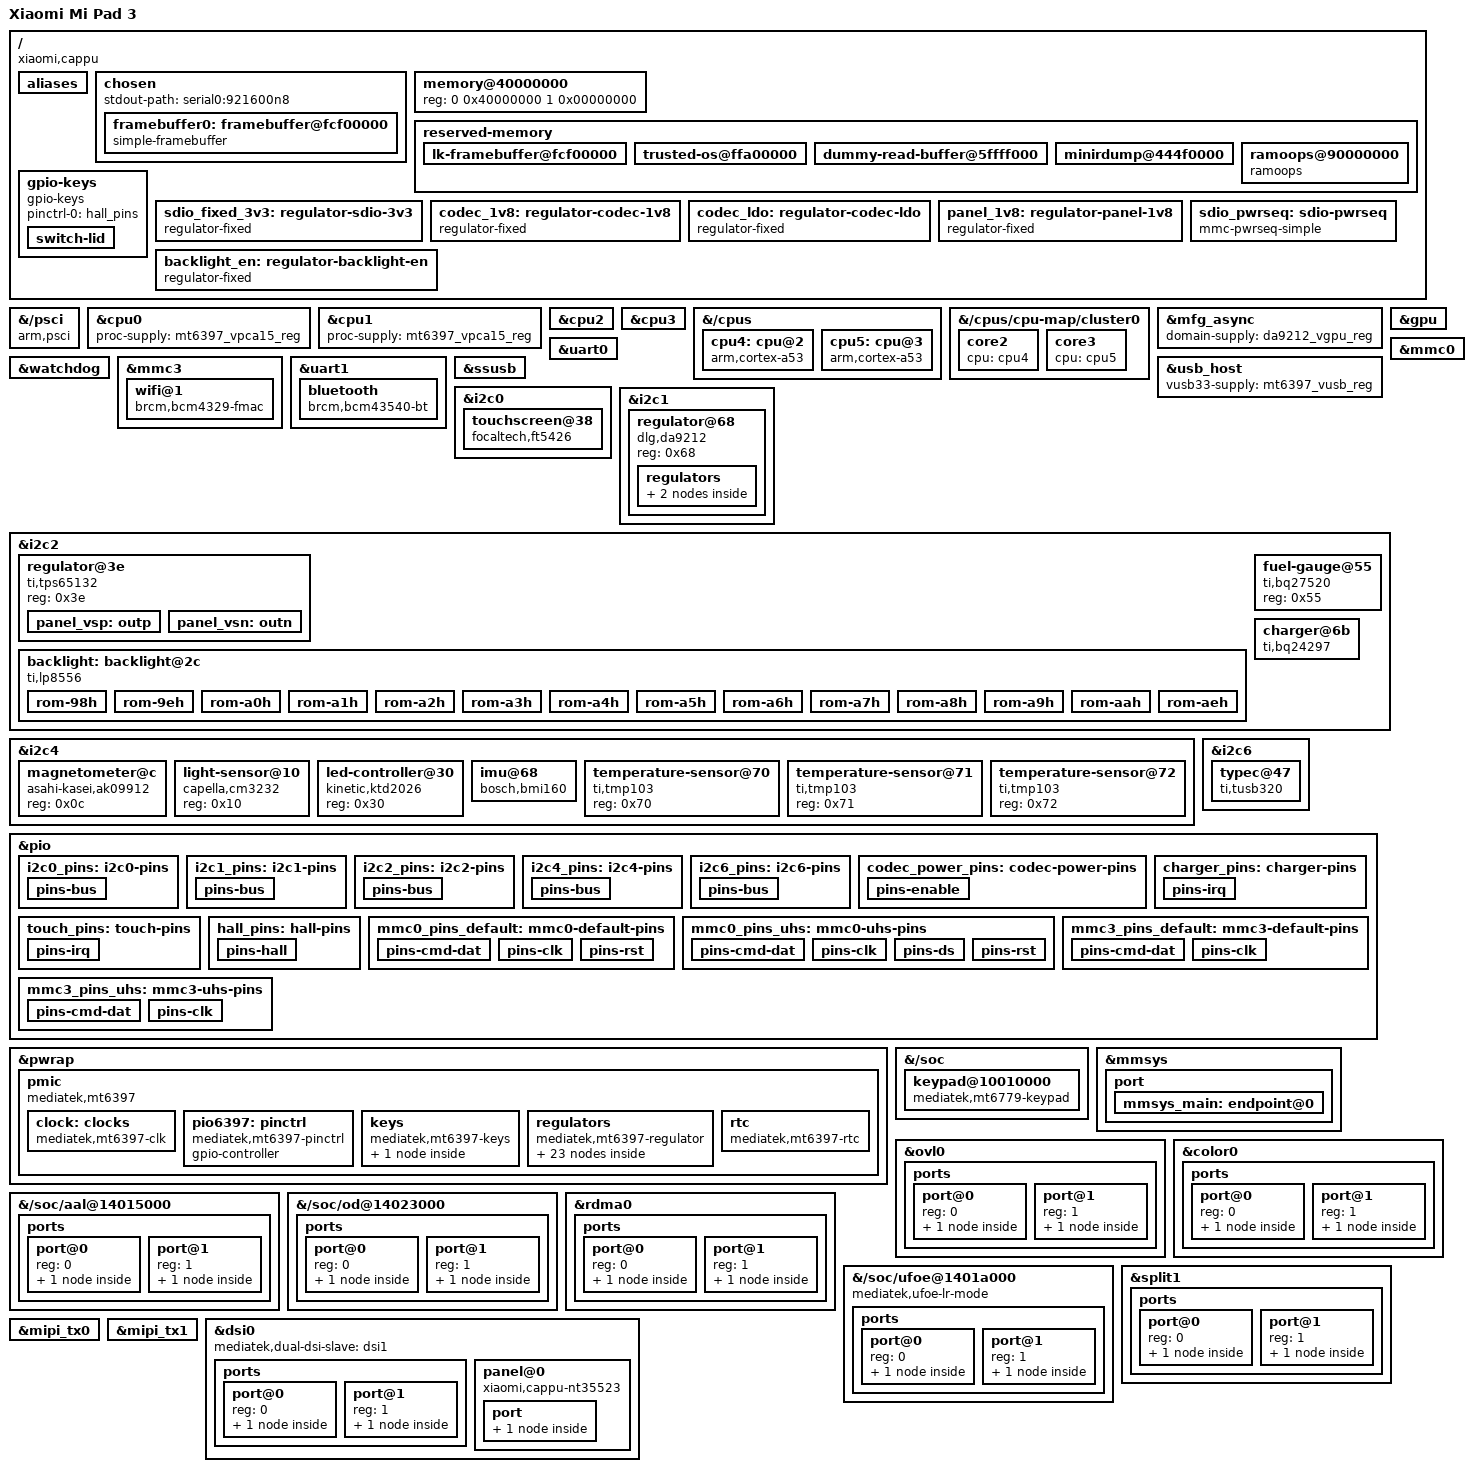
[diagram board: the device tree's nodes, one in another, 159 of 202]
// SPDX-License-Identifier: GPL-2.0-only
/*
 * Xiaomi Mi Pad 3 (cappu): MediaTek MT8176 (MT8173 family, four Cortex-A53 and two
 * Cortex-A72), 4 GB RAM, 1536x2048 dual-link DSI panel.
 *
 * Board facts come from the stock 3.18 device tree (xiaomi8176_tb_c9_n) as the
 * bootloader passes it, the stock I2C device list and the registers the stock LK and
 * kernel leave behind. Layout and PMIC regulator settings follow mt8173-elm.dtsi.
 *
 * Working: all six CPUs, eMMC, USB peripheral, PMIC and DA9212, keys, pstore, charger
 * and fuel gauge, the PowerVR GX6250, and the display through mediatek-drm with panel
 * power and backlight. The BCM4356 Wi-Fi probes.
 * Not yet: IOMMU for the display path, touchscreen, Bluetooth, audio, cameras, USB
 * role switching, cpufreq and cpuidle.
 *
 * The stock LK boots this as an Android boot image and keeps only the first 99
 * characters of the image's command line, so the kernel needs its own
 * (CONFIG_CMDLINE). While the clock, power-domain and regulator handover is not
 * complete it must contain
 *   clk_ignore_unused pd_ignore_unused regulator_ignore_unused
 * See arch/arm64/configs/cappu_spike.config.
 */

/dts-v1/;
#include <dt-bindings/gpio/gpio.h>
#include <dt-bindings/input/input.h>
#include <dt-bindings/interrupt-controller/irq.h>
#include <dt-bindings/pinctrl/mt65xx.h>
#include <dt-bindings/regulator/dlg,da9211-regulator.h>
#include "mt8173.dtsi"

/ {
	model = "Xiaomi Mi Pad 3";
	chassis-type = "tablet";
	compatible = "xiaomi,cappu", "mediatek,mt8173";

	aliases {
		mmc0 = &mmc0;
		mmc1 = &mmc3;
		serial0 = &uart0;
		serial1 = &uart1;
	};

	chosen {
		#address-cells = <2>;
		#size-cells = <2>;
		ranges;
		stdout-path = "serial0:921600n8";

		/*
		 * The bootloader leaves the panel scanning out this buffer (stock fb0: 1536x2048,
		 * 32 bpp, stride 6144, three buffers; the first one is on screen). It is the
		 * console until mediatek-drm binds and removes it; until then nothing may turn
		 * the display path off, hence the *_ignore_unused flags on the command line.
		 */
		framebuffer0: framebuffer@fcf00000 {
			compatible = "simple-framebuffer";
			reg = <0 0xfcf00000 0 (1536 * 2048 * 4)>;
			width = <1536>;
			height = <2048>;
			stride = <(1536 * 4)>;
			/* proven by the canary payload: red written as 0xffff0000 shows blue */
			format = "a8b8g8r8";
			/* holds the display power domain on while simpledrm is bound */
			power-domains = <&spm MT8173_POWER_DOMAIN_MM>;
		};
	};

	memory@40000000 {
		device_type = "memory";
		/* 4 GB at 0x40000000-0x13fffffff; the bootloader rewrites this node */
		reg = <0 0x40000000 1 0x00000000>;
	};

	/*
	 * LK (boot_linux_fdt, via the helper at 0x41e0447c) adds two nodes here before
	 * starting the kernel: secos-reserved-memory (0xffa00000, 6 MB, trusted OS) and
	 * fb-reserved-memory (0xfcf00000, 43 MB, its framebuffer), both no-map. This node
	 * must exist and must not already contain nodes with those names: if
	 * fdt_add_subnode() fails, LK prints a warning and then refuses to boot.
	 */
	reserved-memory {
		#address-cells = <2>;
		#size-cells = <2>;
		ranges;

		/*
		 * The same two regions LK adds as fb-reserved-memory and
		 * secos-reserved-memory, under other names so LK's fdt_add_subnode() still
		 * succeeds. Spike boots 1-3 went black, with no earlycon text, consistent with
		 * these not being reserved: swiotlb's zeroed 64 MB below 4 GB would cover
		 * the scanned-out framebuffer and the trusted OS. Overlap with LK's nodes only
		 * costs an "OVERLAP DETECTED" message.
		 */
		lk-framebuffer@fcf00000 {
			reg = <0 0xfcf00000 0 0x2b00000>;
			no-map;
		};

		trusted-os@ffa00000 {
			reg = <0 0xffa00000 0 0x600000>;
			no-map;
		};

		/* stock: "vcore_dvfs-reserve-memory", read by the DRAM DVFS hardware */
		dummy-read-buffer@5ffff000 {
			reg = <0 0x5ffff000 0 0x2000>;
			no-map;
		};

		/* stock: "minirdump-reserve-memory", crash record area read by LK */
		minirdump@444f0000 {
			reg = <0 0x444f0000 0 0x10000>;
			no-map;
		};

		/*
		 * pstore, so the log of a failed boot can be read after the next one. Not the
		 * stock RAM console at 0x44400000: recovery clears that (seen on the MT8173
		 * Fire HD 10, which uses this address). Clear of every LK buffer: kernel
		 * 0x40080000-0x41c80000, LK 0x41e00000, staging 0x45000000, ramdisk
		 * 0x49000000, DTB 0x4e000000.
		 */
		/*
		 * Laid out so LineageOS's 3.18 ramoops reads the console zone after a warm
		 * reset. Its command line can only carry ramoops.mem_address=0x90000000
		 * ramoops.mem_size=0xc0000 (LK keeps 99 characters), and with its default zone
		 * sizes its console zone is 0x9007f000 + 0x10000. Here: 0x7f000 of 0x1000
		 * dmesg records, then the 0x10000 console zone at the same address.
		 */
		ramoops@90000000 {
			compatible = "ramoops";
			reg = <0 0x90000000 0 0x8f000>;
			console-size = <0x10000>;
			record-size = <0x1000>;
		};
	};

	gpio-keys {
		compatible = "gpio-keys";
		pinctrl-names = "default";
		pinctrl-0 = <&hall_pins>;

		/* stock "lid_front" */
		switch-lid {
			label = "Cover";
			gpios = <&pio 116 GPIO_ACTIVE_LOW>;
			linux,input-type = <EV_SW>;
			linux,code = <SW_LID>;
			wakeup-source;
		};

		/*
		 * The second hall sensor ("lid_back", GPIO70, active low) reports switch 0x12 on
		 * stock, a Xiaomi-only code above SW_MAX. It has no standard meaning, so it is
		 * left out.
		 */
	};

	/* BCM4356 module supply: comes straight from the system rail, not switchable */
	sdio_fixed_3v3: regulator-sdio-3v3 {
		compatible = "regulator-fixed";
		regulator-name = "sdio_3v3";
		regulator-min-microvolt = <3300000>;
		regulator-max-microvolt = <3300000>;
		regulator-always-on;
	};

	/*
	 * RT5659 codec supplies: 1.8 V (stock 1v8-gpio, GPIO34) and the codec LDO (stock
	 * ldo-gpio, GPIO35). LK leaves both pins muxed to PCM0, so both rails are off, and
	 * with both off the unpowered codec holds SDA and SCL of i2c6 low: every transfer
	 * on that bus times out, the USB-C controller's included. Either rail frees the
	 * bus (measured). Kept on until a codec driver takes them.
	 */
	codec_1v8: regulator-codec-1v8 {
		compatible = "regulator-fixed";
		regulator-name = "codec_1v8";
		regulator-min-microvolt = <1800000>;
		regulator-max-microvolt = <1800000>;
		gpio = <&pio 34 GPIO_ACTIVE_HIGH>;
		enable-active-high;
		pinctrl-names = "default";
		pinctrl-0 = <&codec_power_pins>;
		regulator-boot-on;
		regulator-always-on;
	};

	codec_ldo: regulator-codec-ldo {
		compatible = "regulator-fixed";
		regulator-name = "codec_ldo";
		gpio = <&pio 35 GPIO_ACTIVE_HIGH>;
		enable-active-high;
		regulator-boot-on;
		regulator-always-on;
	};

	/* Panel logic supply (stock GPIO_LCD_1V8_EN, GPIO71); LK hands over with it on */
	panel_1v8: regulator-panel-1v8 {
		compatible = "regulator-fixed";
		regulator-name = "panel_1v8";
		regulator-min-microvolt = <1800000>;
		regulator-max-microvolt = <1800000>;
		gpio = <&pio 71 GPIO_ACTIVE_HIGH>;
		enable-active-high;
		regulator-boot-on;
	};

	/* LP8556 enable pin (stock lp8556_gpio_enable, GPIO103); on at handover */
	backlight_en: regulator-backlight-en {
		compatible = "regulator-fixed";
		regulator-name = "backlight_en";
		gpio = <&pio 103 GPIO_ACTIVE_HIGH>;
		enable-active-high;
		regulator-boot-on;
	};

	/* BCM4356 WL_REG_ON (stock wifi_reg_on: GPIO31) */
	sdio_pwrseq: sdio-pwrseq {
		compatible = "mmc-pwrseq-simple";
		reset-gpios = <&pio 31 GPIO_ACTIVE_LOW>;
		post-power-on-delay-ms = <50>;
	};
};

/*
 * Stock firmware declares PSCI 0.1 only (its PSCI 0.2 is broken on the MT8173 Fire HD 10
 * too); mt8173.dtsi already carries the stock function IDs. Stock "mt-boot" is PSCI CPU_ON
 * followed by the kernel powering the core through SPM MTCMOS: this firmware's CPU_ON
 * does not power cores. drivers/soc/mediatek/mtk-cpu-mtcmos.c (from the Fire HD 10 port,
 * extended to the MT8176's four A53s) does that after CPU_ON. CPU idle states need
 * CPU_SUSPEND, which has the same gap.
 */
&{/psci} {
	compatible = "arm,psci";
};

&cpu0 {
	/delete-property/ cpu-idle-states;
	proc-supply = <&mt6397_vpca15_reg>;
};

&cpu1 {
	/delete-property/ cpu-idle-states;
	proc-supply = <&mt6397_vpca15_reg>;
};

&cpu2 {
	/delete-property/ cpu-idle-states;
	proc-supply = <&da9212_vcpu_reg>;
	sram-supply = <&mt6397_vsramca7_reg>;
};

&cpu3 {
	/delete-property/ cpu-idle-states;
	proc-supply = <&da9212_vcpu_reg>;
	sram-supply = <&mt6397_vsramca7_reg>;
};

/*
 * MT8176 has four A53s in cluster 0 (MPIDR 0x0-0x3) and two A72s in cluster 1; the
 * stock ATF log brings up mt_on[0:1..3] and [256:0..1]. mt8173.dtsi describes the
 * MT8173's 2+2, so add the two extra A53s. Their logical numbers come after the
 * A72s (DT order): 0-1 A53, 2-3 A72, 4-5 A53.
 */
&{/cpus} {
	cpu4: cpu@2 {
		device_type = "cpu";
		compatible = "arm,cortex-a53";
		reg = <0x002>;
		enable-method = "psci";
		#cooling-cells = <2>;
		dynamic-power-coefficient = <263>;
		clocks = <&infracfg CLK_INFRA_CA53SEL>,
			 <&apmixedsys CLK_APMIXED_MAINPLL>;
		clock-names = "cpu", "intermediate";
		operating-points-v2 = <&cluster0_opp>;
		capacity-dmips-mhz = <740>;
		proc-supply = <&mt6397_vpca15_reg>;
	};

	cpu5: cpu@3 {
		device_type = "cpu";
		compatible = "arm,cortex-a53";
		reg = <0x003>;
		enable-method = "psci";
		#cooling-cells = <2>;
		dynamic-power-coefficient = <263>;
		clocks = <&infracfg CLK_INFRA_CA53SEL>,
			 <&apmixedsys CLK_APMIXED_MAINPLL>;
		clock-names = "cpu", "intermediate";
		operating-points-v2 = <&cluster0_opp>;
		capacity-dmips-mhz = <740>;
		proc-supply = <&mt6397_vpca15_reg>;
	};
};

&{/cpus/cpu-map/cluster0} {
	core2 {
		cpu = <&cpu4>;
	};

	core3 {
		cpu = <&cpu5>;
	};
};

&mfg_async {
	domain-supply = <&da9212_vgpu_reg>;
};

/*
 * SMI and M4U. mediatek-drm needs the IOMMU to scan out buffers that are not
 * physically contiguous, which is what the GPU driver hands it (Vulkan presenting
 * straight to the panel).
 *
 * All six larbs stay enabled, as in mt8173.dtsi: the IOMMU driver refuses to register
 * if any device with an "iommus" property sits on a larb that is not there (-EINVAL
 * from its probe_device), and the codec, camera and MDP nodes all have one.
 *
 * LK hands over with OVL0 reading its framebuffer by physical address through larb0.
 * When larb0 is first resumed for the overlay driver's probe, that read goes through
 * the IOMMU and faults (and the larb's clocks are gated again after the probe) until
 * mediatek-drm, a few milliseconds later, stops LK's stream and programs its own
 * buffer. That costs a burst of "fault" messages and nothing else.
 */

/* PowerVR GX6250: needs powervr.exp_hw_support=1 and firmware rogue_4.40.2.51_v1.fw */
&gpu {
	status = "okay";
};

/* stock console ttyMT0 at 921600, on test pads */
&uart0 {
	status = "okay";
};

&watchdog {
	/*
	 * LK leaves it disabled (a halted payload sat for many minutes without a reset).
	 * Keep the external (PMIC) reset: a TOPRGU reset without it, tried on 2026-11-21,
	 * left the board stuck with a black screen and no preloader on USB.
	 */
	status = "okay";
};

&mmc0 {
	status = "okay";
	pinctrl-names = "default", "state_uhs";
	pinctrl-0 = <&mmc0_pins_default>;
	pinctrl-1 = <&mmc0_pins_uhs>;
	bus-width = <8>;
	max-frequency = <200000000>;
	cap-mmc-highspeed;
	mmc-hs200-1_8v;
	mmc-hs400-1_8v;
	cap-mmc-hw-reset;
	hs400-ds-delay = <0x14015>;
	/* stock hs200_cmd_int_delay and hs400_cmd_int_delay; stock cmd_resp_sel is 0 */
	mediatek,hs200-cmd-int-delay = <26>;
	mediatek,hs400-cmd-int-delay = <14>;
	vmmc-supply = <&mt6397_vemc_3v3_reg>;
	vqmmc-supply = <&mt6397_vio18_reg>;
	assigned-clocks = <&topckgen CLK_TOP_MSDC50_0_SEL>;
	assigned-clock-parents = <&topckgen CLK_TOP_MSDCPLL_D2>;
	non-removable;
};

/*
 * BCM4356 Wi-Fi. Needs brcmfmac4356-sdio.bin and the board nvram from the stock vendor
 * image. The chip also needs the MT6397 RTC 32 kHz output (RTC_CON.F32KOB clear), which
 * stock switches on with rtc_gpio_enable_32k() before raising WL_REG_ON. Mainline has no
 * consumer for it; the bit is battery-backed, so it stays as stock last left it.
 */
&mmc3 {
	status = "okay";
	pinctrl-names = "default", "state_uhs";
	pinctrl-0 = <&mmc3_pins_default>;
	pinctrl-1 = <&mmc3_pins_uhs>;
	bus-width = <4>;
	max-frequency = <200000000>;
	cap-sd-highspeed;
	sd-uhs-sdr50;
	sd-uhs-sdr104;
	keep-power-in-suspend;
	wakeup-source;
	cap-sdio-irq;
	cap-power-off-card;
	non-removable;
	mmc-pwrseq = <&sdio_pwrseq>;
	vmmc-supply = <&sdio_fixed_3v3>;
	/* stock declares no supplies; the module I/O is 1.8 V */
	vqmmc-supply = <&mt6397_vio18_reg>;
	#address-cells = <1>;
	#size-cells = <0>;

	wifi@1 {
		compatible = "brcm,bcm4329-fmac";
		reg = <1>;
		/*
		 * stock wifi_host_wake: GPIO30, used by bcmdhd as a level-high OOB interrupt
		 * (the "interrupts = <2 ...>" in the stock node is unused)
		 */
		interrupts-extended = <&pio 30 IRQ_TYPE_LEVEL_HIGH>;
		interrupt-names = "host-wake";
	};
};

/* BCM4356 Bluetooth on UART1 (stock /dev/ttyMT1), H4 with RTS/CTS */
&uart1 {
	status = "okay";
	/* TODO stage 2: RTS/CTS pin mux, taken from the stock uart1 pin states */

	bluetooth {
		/* the Bluetooth core of the BCM4356 is a BCM4354A2 */
		compatible = "brcm,bcm43540-bt";
		max-speed = <3000000>;
		shutdown-gpios = <&pio 32 GPIO_ACTIVE_HIGH>;		/* stock bcm_bt_reg_on */
		device-wakeup-gpios = <&pio 28 GPIO_ACTIVE_HIGH>;	/* stock bcm_bt_dev_wake */
		host-wakeup-gpios = <&pio 37 GPIO_ACTIVE_HIGH>;		/* stock bcm_bt_host_wake */
	};
};

/*
 * USB-C, USB 2.0 only. Peripheral mode for adb/RNDIS during bring-up.
 * TODO: role switching from the TUSB320.
 */
&ssusb {
	dr_mode = "peripheral";
	vusb33-supply = <&mt6397_vusb_reg>;
	status = "okay";
};

&usb_host {
	vusb33-supply = <&mt6397_vusb_reg>;
	status = "okay";
};

/* I2C: controller numbering matches the stock tree; the stock Linux bus number is N + 4 */

&i2c0 {
	status = "okay";
	pinctrl-names = "default";
	pinctrl-0 = <&i2c0_pins>;
	clock-frequency = <400000>;

	touchscreen@38 {
		/* FocalTech FT5x46; register map of the FT5426/FT5506 family */
		compatible = "focaltech,ft5426";
		reg = <0x38>;
		interrupts-extended = <&pio 104 IRQ_TYPE_EDGE_FALLING>;
		pinctrl-names = "default";
		pinctrl-0 = <&touch_pins>;
		reset-gpios = <&pio6397 12 GPIO_ACTIVE_LOW>;
		/* stock: vtouch = VGP6 (3.3 V), vtouchio = VGP4 (1.8 V) */
		vcc-supply = <&mt6397_vgp6_reg>;
		iovcc-supply = <&mt6397_vgp4_reg>;
		touchscreen-size-x = <1536>;
		touchscreen-size-y = <2048>;
	};
};

/* CPU and GPU buck */
&i2c1 {
	status = "okay";
	pinctrl-names = "default";
	pinctrl-0 = <&i2c1_pins>;
	clock-frequency = <1500000>;

	regulator@68 {
		compatible = "dlg,da9212";
		reg = <0x68>;
		/*
		 * The stock tree wires no interrupt (the Chromebooks use GPIO15). The driver runs
		 * without one; the binding wants one, so this fails dtbs_check until the pin is
		 * known or the binding relaxed.
		 */

		regulators {
			da9212_vcpu_reg: BUCKA {
				regulator-name = "VBUCKA";
				regulator-min-microvolt = <700000>;
				regulator-max-microvolt = <1310000>;
				regulator-min-microamp = <2000000>;
				regulator-max-microamp = <4400000>;
				regulator-ramp-delay = <10000>;
				regulator-always-on;
				/* stock: enable on PMIC GPIO24 */
				enable-gpios = <&pio6397 24 GPIO_ACTIVE_HIGH>;
				regulator-allowed-modes = <DA9211_BUCK_MODE_SYNC
							   DA9211_BUCK_MODE_AUTO>;
			};

			da9212_vgpu_reg: BUCKB {
				regulator-name = "VBUCKB";
				regulator-min-microvolt = <700000>;
				regulator-max-microvolt = <1310000>;
				regulator-min-microamp = <2000000>;
				regulator-max-microamp = <3000000>;
				regulator-ramp-delay = <10000>;
			};
		};
	};
};

/* battery, charger, backlight, panel bias */
&i2c2 {
	status = "okay";
	pinctrl-names = "default";
	pinctrl-0 = <&i2c2_pins>;
	clock-frequency = <400000>;

	/*
	 * Panel bias, +/-5.6 V as the stock driver programs it (register value 0x10).
	 * Positive rail enable is GPIO8, negative GPIO13; both on at handover.
	 */
	regulator@3e {
		compatible = "ti,tps65132";
		reg = <0x3e>;

		panel_vsp: outp {
			regulator-name = "panel_vsp";
			regulator-min-microvolt = <5600000>;
			regulator-max-microvolt = <5600000>;
			enable-gpios = <&pio 8 GPIO_ACTIVE_HIGH>;
			regulator-boot-on;
		};

		panel_vsn: outn {
			regulator-name = "panel_vsn";
			regulator-min-microvolt = <5600000>;
			regulator-max-microvolt = <5600000>;
			enable-gpios = <&pio 13 GPIO_ACTIVE_HIGH>;
			regulator-boot-on;
		};
	};

	/*
	 * Backlight. Control mode and EPROM values are the stock tree's: brightness is
	 * the I2C register times the PWM the panel itself outputs (its CABC), which
	 * the panel driver leaves at full scale.
	 */
	backlight: backlight@2c {
		compatible = "ti,lp8556";
		reg = <0x2c>;
		enable-supply = <&backlight_en>;
		bl-name = "lcd-backlight";
		dev-ctrl = /bits/ 8 <0x83>;
		init-brt = /bits/ 8 <0x50>;

		rom-98h {
			rom-addr = /bits/ 8 <0x98>;
			rom-val = /bits/ 8 <0x80>;
		};

		rom-9eh {
			rom-addr = /bits/ 8 <0x9e>;
			rom-val = /bits/ 8 <0x21>;
		};

		rom-a0h {
			rom-addr = /bits/ 8 <0xa0>;
			rom-val = /bits/ 8 <0xff>;
		};

		rom-a1h {
			rom-addr = /bits/ 8 <0xa1>;
			rom-val = /bits/ 8 <0x3f>;
		};

		rom-a2h {
			rom-addr = /bits/ 8 <0xa2>;
			rom-val = /bits/ 8 <0x20>;
		};

		rom-a3h {
			rom-addr = /bits/ 8 <0xa3>;
			rom-val = /bits/ 8 <0x58>;
		};

		rom-a4h {
			rom-addr = /bits/ 8 <0xa4>;
			rom-val = /bits/ 8 <0x72>;
		};

		rom-a5h {
			rom-addr = /bits/ 8 <0xa5>;
			rom-val = /bits/ 8 <0x24>;
		};

		rom-a6h {
			rom-addr = /bits/ 8 <0xa6>;
			rom-val = /bits/ 8 <0x80>;
		};

		rom-a7h {
			rom-addr = /bits/ 8 <0xa7>;
			rom-val = /bits/ 8 <0xf5>;
		};

		rom-a8h {
			rom-addr = /bits/ 8 <0xa8>;
			rom-val = /bits/ 8 <0x24>;
		};

		rom-a9h {
			rom-addr = /bits/ 8 <0xa9>;
			rom-val = /bits/ 8 <0xb2>;
		};

		rom-aah {
			rom-addr = /bits/ 8 <0xaa>;
			rom-val = /bits/ 8 <0x8f>;
		};

		rom-aeh {
			rom-addr = /bits/ 8 <0xae>;
			rom-val = /bits/ 8 <0x0f>;
		};
	};

	fuel-gauge@55 {
		compatible = "ti,bq27520";
		reg = <0x55>;
	};

	charger@6b {
		compatible = "ti,bq24297";
		reg = <0x6b>;
		/* stock: EINT105, falling edge; the pin (MSDC2_CMD) must be muxed as GPIO */
		interrupts-extended = <&pio 105 IRQ_TYPE_EDGE_FALLING>;
		pinctrl-names = "default";
		pinctrl-0 = <&charger_pins>;
		/*
		 * Keep LK's charger setup. A register reset drops the input current limit to
		 * the defaults, below what the tablet draws with its screen on, so it drains
		 * while plugged in (flat battery on 2026-11-22).
		 */
		disable-reset;
	};
};

/* i2c3: cameras (no mainline driver for the MT8173 camera ISP) */

&i2c4 {
	status = "okay";
	pinctrl-names = "default";
	pinctrl-0 = <&i2c4_pins>;
	clock-frequency = <400000>;

	magnetometer@c {
		compatible = "asahi-kasei,ak09912";
		reg = <0x0c>;
	};

	light-sensor@10 {
		compatible = "capella,cm3232";
		reg = <0x10>;
	};

	led-controller@30 {
		compatible = "kinetic,ktd2026";
		reg = <0x30>;
		#address-cells = <1>;
		#size-cells = <0>;
		/* TODO: LED channel nodes */
	};

	/* stock splits this chip into gsensor@68 and gyro@69; it is one BMI160 */
	imu@68 {
		compatible = "bosch,bmi160";
		reg = <0x68>;
		interrupts-extended = <&pio 14 IRQ_TYPE_EDGE_RISING>;
	};

	temperature-sensor@70 {
		compatible = "ti,tmp103";
		reg = <0x70>;
	};

	temperature-sensor@71 {
		compatible = "ti,tmp103";
		reg = <0x71>;
	};

	temperature-sensor@72 {
		compatible = "ti,tmp103";
		reg = <0x72>;
	};
};

&i2c6 {
	status = "okay";
	pinctrl-names = "default";
	pinctrl-0 = <&i2c6_pins>;
	clock-frequency = <400000>;

	/*
	 * TODO stage 2: RT5659 codec at 0x1b (irq GPIO36, reset GPIO33, 1.8 V enable GPIO34,
	 * LDO enable GPIO35), TFA98xx amplifiers at 0x34 and 0x37, and a machine driver for
	 * the MT8173 AFE with this codec.
	 */

	/*
	 * The stock tree says 0x60, but the device answers at 0x47. No driver binds in the
	 * spike (extcon-usbc-tusb320 is not built in); init sets the chip up instead, see
	 * usbc_sink() in cappu-helper.c. Mainline's driver would need two things first:
	 * clear DISABLE_RD_RP (register 0x45 bit 2), which the stock kernel's shutdown can
	 * leave set, and prefer the sink role, since this board cannot source VBUS.
	 */
	typec@47 {
		compatible = "ti,tusb320";
		reg = <0x47>;
		interrupts-extended = <&pio 88 IRQ_TYPE_LEVEL_LOW>;
	};
};

&pio {
	/*
	 * I2C pin states from the stock tree. LK only muxes the buses it uses itself (i2c1
	 * and i2c2); without these, transfers on the others time out.
	 */
	i2c0_pins: i2c0-pins {
		pins-bus {
			pinmux = <MT8173_PIN_45_SDA0__FUNC_SDA0>,
				 <MT8173_PIN_46_SCL0__FUNC_SCL0>;
			bias-disable;
		};
	};

	i2c1_pins: i2c1-pins {
		pins-bus {
			pinmux = <MT8173_PIN_125_SDA1__FUNC_SDA1>,
				 <MT8173_PIN_126_SCL1__FUNC_SCL1>;
			bias-disable;
		};
	};

	i2c2_pins: i2c2-pins {
		pins-bus {
			pinmux = <MT8173_PIN_43_SDA2__FUNC_SDA2>,
				 <MT8173_PIN_44_SCL2__FUNC_SCL2>;
			bias-disable;
		};
	};

	i2c4_pins: i2c4-pins {
		pins-bus {
			pinmux = <MT8173_PIN_133_SDA4__FUNC_SDA4>,
				 <MT8173_PIN_134_SCL4__FUNC_SCL4>;
			bias-disable;
		};
	};

	/* the pad function is named SDA5/SCL5; it belongs to the controller at 0x11013000 */
	i2c6_pins: i2c6-pins {
		pins-bus {
			pinmux = <MT8173_PIN_100_MSDC2_DAT0__FUNC_SDA5>,
				 <MT8173_PIN_101_MSDC2_DAT1__FUNC_SCL5>;
			bias-disable;
		};
	};

	codec_power_pins: codec-power-pins {
		pins-enable {
			pinmux = <MT8173_PIN_34_DAIPCMIN__FUNC_GPIO34>,
				 <MT8173_PIN_35_DAIPCMOUT__FUNC_GPIO35>;
			bias-disable;
		};
	};

	charger_pins: charger-pins {
		pins-irq {
			pinmux = <MT8173_PIN_105_MSDC2_CMD__FUNC_GPIO105>;
			input-enable;
			bias-pull-up;
		};
	};

	touch_pins: touch-pins {
		pins-irq {
			pinmux = <MT8173_PIN_104_MSDC2_CLK__FUNC_GPIO104>;
			input-enable;
			bias-pull-up;
		};
	};

	hall_pins: hall-pins {
		pins-hall {
			pinmux = <MT8173_PIN_116_UCTS0__FUNC_GPIO116>,
				 <MT8173_PIN_70_SPI_MI__FUNC_GPIO70>;
			input-enable;
			bias-pull-up;
		};
	};

	/* MSDC pin settings below are the stock values */
	mmc0_pins_default: mmc0-default-pins {
		pins-cmd-dat {
			pinmux = <MT8173_PIN_57_MSDC0_DAT0__FUNC_MSDC0_DAT0>,
				 <MT8173_PIN_58_MSDC0_DAT1__FUNC_MSDC0_DAT1>,
				 <MT8173_PIN_59_MSDC0_DAT2__FUNC_MSDC0_DAT2>,
				 <MT8173_PIN_60_MSDC0_DAT3__FUNC_MSDC0_DAT3>,
				 <MT8173_PIN_61_MSDC0_DAT4__FUNC_MSDC0_DAT4>,
				 <MT8173_PIN_62_MSDC0_DAT5__FUNC_MSDC0_DAT5>,
				 <MT8173_PIN_63_MSDC0_DAT6__FUNC_MSDC0_DAT6>,
				 <MT8173_PIN_64_MSDC0_DAT7__FUNC_MSDC0_DAT7>,
				 <MT8173_PIN_66_MSDC0_CMD__FUNC_MSDC0_CMD>;
			input-enable;
			bias-pull-up;
		};

		pins-clk {
			pinmux = <MT8173_PIN_65_MSDC0_CLK__FUNC_MSDC0_CLK>;
			bias-pull-down;
		};

		pins-rst {
			pinmux = <MT8173_PIN_68_MSDC0_RST___FUNC_MSDC0_RSTB>;
			bias-pull-up;
		};
	};

	mmc0_pins_uhs: mmc0-uhs-pins {
		pins-cmd-dat {
			pinmux = <MT8173_PIN_57_MSDC0_DAT0__FUNC_MSDC0_DAT0>,
				 <MT8173_PIN_58_MSDC0_DAT1__FUNC_MSDC0_DAT1>,
				 <MT8173_PIN_59_MSDC0_DAT2__FUNC_MSDC0_DAT2>,
				 <MT8173_PIN_60_MSDC0_DAT3__FUNC_MSDC0_DAT3>,
				 <MT8173_PIN_61_MSDC0_DAT4__FUNC_MSDC0_DAT4>,
				 <MT8173_PIN_62_MSDC0_DAT5__FUNC_MSDC0_DAT5>,
				 <MT8173_PIN_63_MSDC0_DAT6__FUNC_MSDC0_DAT6>,
				 <MT8173_PIN_64_MSDC0_DAT7__FUNC_MSDC0_DAT7>,
				 <MT8173_PIN_66_MSDC0_CMD__FUNC_MSDC0_CMD>;
			input-enable;
			drive-strength = <MTK_DRIVE_6mA>;
			bias-pull-up = <MTK_PUPD_SET_R1R0_01>;
		};

		pins-clk {
			pinmux = <MT8173_PIN_65_MSDC0_CLK__FUNC_MSDC0_CLK>;
			drive-strength = <MTK_DRIVE_6mA>;
			bias-pull-down = <MTK_PUPD_SET_R1R0_10>;
		};

		pins-ds {
			pinmux = <MT8173_PIN_67_MSDC0_DSL__FUNC_MSDC0_DSL>;
			drive-strength = <MTK_DRIVE_8mA>;
			bias-pull-down = <MTK_PUPD_SET_R1R0_10>;
		};

		pins-rst {
			pinmux = <MT8173_PIN_68_MSDC0_RST___FUNC_MSDC0_RSTB>;
			bias-pull-up;
		};
	};

	mmc3_pins_default: mmc3-default-pins {
		pins-cmd-dat {
			pinmux = <MT8173_PIN_22_MSDC3_DAT0__FUNC_MSDC3_DAT0>,
				 <MT8173_PIN_23_MSDC3_DAT1__FUNC_MSDC3_DAT1>,
				 <MT8173_PIN_24_MSDC3_DAT2__FUNC_MSDC3_DAT2>,
				 <MT8173_PIN_25_MSDC3_DAT3__FUNC_MSDC3_DAT3>,
				 <MT8173_PIN_27_MSDC3_CMD__FUNC_MSDC3_CMD>;
			input-enable;
			drive-strength = <MTK_DRIVE_4mA>;
			bias-pull-up = <MTK_PUPD_SET_R1R0_10>;
		};

		pins-clk {
			pinmux = <MT8173_PIN_26_MSDC3_CLK__FUNC_MSDC3_CLK>;
			drive-strength = <MTK_DRIVE_4mA>;
			bias-pull-down;
		};
	};

	mmc3_pins_uhs: mmc3-uhs-pins {
		pins-cmd-dat {
			pinmux = <MT8173_PIN_22_MSDC3_DAT0__FUNC_MSDC3_DAT0>,
				 <MT8173_PIN_23_MSDC3_DAT1__FUNC_MSDC3_DAT1>,
				 <MT8173_PIN_24_MSDC3_DAT2__FUNC_MSDC3_DAT2>,
				 <MT8173_PIN_25_MSDC3_DAT3__FUNC_MSDC3_DAT3>,
				 <MT8173_PIN_27_MSDC3_CMD__FUNC_MSDC3_CMD>;
			input-enable;
			drive-strength = <MTK_DRIVE_4mA>;
			bias-pull-up = <MTK_PUPD_SET_R1R0_10>;
		};

		pins-clk {
			pinmux = <MT8173_PIN_26_MSDC3_CLK__FUNC_MSDC3_CLK>;
			drive-strength = <MTK_DRIVE_4mA>;
			bias-pull-down = <MTK_PUPD_SET_R1R0_10>;
		};
	};
};

&pwrap {
	pmic: pmic {
		compatible = "mediatek,mt6397";
		/* stock: EINT5, level high (the Chromebooks use GPIO11) */
		interrupts-extended = <&pio 5 IRQ_TYPE_LEVEL_HIGH>;
		interrupt-controller;
		#interrupt-cells = <2>;

		clock: clocks {
			compatible = "mediatek,mt6397-clk";
			#clock-cells = <1>;
		};

		pio6397: pinctrl {
			compatible = "mediatek,mt6397-pinctrl";
			gpio-controller;
			#gpio-cells = <2>;
		};

		keys {
			compatible = "mediatek,mt6397-keys";
			/*
			 * Keep the PMIC's power-key long-press reset on. Without this property
			 * the driver disables it, and a stuck kernel can then only be stopped
			 * by draining the battery (2026-11-21). The value is the raw PMIC
			 * reset-timer code; 0 should be about 8 s.
			 */
			mediatek,long-press-mode = <1>;
			power-off-time-sec = <0>;

			key-power {
				linux,keycodes = <KEY_POWER>;
				wakeup-source;
			};
		};

		/*
		 * Ranges and always-on flags are the stock ones, so no LDO voltage is forced at
		 * probe. Ramp delays come from mt8173-elm.
		 */
		regulators {
			compatible = "mediatek,mt6397-regulator";

			mt6397_vpca15_reg: buck_vpca15 {
				regulator-name = "vpca15";
				regulator-min-microvolt = <700000>;
				regulator-max-microvolt = <1350000>;
				regulator-ramp-delay = <12500>;
				regulator-always-on;
				regulator-allowed-modes = <0 1>;
			};

			mt6397_vpca7_reg: buck_vpca7 {
				regulator-name = "vpca7";
				regulator-min-microvolt = <700000>;
				regulator-max-microvolt = <1350000>;
				regulator-ramp-delay = <12500>;
				regulator-enable-ramp-delay = <115>;
				regulator-always-on;
			};

			mt6397_vsramca15_reg: buck_vsramca15 {
				regulator-name = "vsramca15";
				regulator-min-microvolt = <700000>;
				regulator-max-microvolt = <1350000>;
				regulator-ramp-delay = <12500>;
				regulator-always-on;
			};

			mt6397_vsramca7_reg: buck_vsramca7 {
				regulator-name = "vsramca7";
				regulator-min-microvolt = <700000>;
				regulator-max-microvolt = <1350000>;
				regulator-ramp-delay = <12500>;
				regulator-always-on;
			};

			mt6397_vcore_reg: buck_vcore {
				regulator-name = "vcore";
				regulator-min-microvolt = <700000>;
				regulator-max-microvolt = <1350000>;
				regulator-ramp-delay = <12500>;
				regulator-always-on;
			};

			mt6397_vgpu_reg: buck_vgpu {
				regulator-name = "vgpu";
				regulator-min-microvolt = <700000>;
				regulator-max-microvolt = <1350000>;
				regulator-ramp-delay = <12500>;
				regulator-enable-ramp-delay = <115>;
			};

			mt6397_vdrm_reg: buck_vdrm {
				regulator-name = "vdrm";
				regulator-min-microvolt = <1200000>;
				regulator-max-microvolt = <1400000>;
				regulator-ramp-delay = <12500>;
				regulator-always-on;
			};

			mt6397_vio18_reg: buck_vio18 {
				regulator-name = "vio18";
				regulator-min-microvolt = <1620000>;
				regulator-max-microvolt = <1980000>;
				regulator-ramp-delay = <12500>;
				regulator-always-on;
			};

			mt6397_vtcxo_reg: ldo_vtcxo {
				regulator-name = "vtcxo";
				regulator-always-on;
			};

			mt6397_va28_reg: ldo_va28 {
				regulator-name = "va28";
				regulator-always-on;
			};

			mt6397_vcama_reg: ldo_vcama {
				regulator-name = "vcama";
				regulator-min-microvolt = <1500000>;
				regulator-max-microvolt = <2800000>;
				regulator-enable-ramp-delay = <218>;
			};

			mt6397_vio28_reg: ldo_vio28 {
				regulator-name = "vio28";
				regulator-always-on;
			};

			mt6397_vusb_reg: ldo_vusb {
				regulator-name = "vusb";
			};

			mt6397_vmc_reg: ldo_vmc {
				regulator-name = "vmc";
				regulator-min-microvolt = <1800000>;
				regulator-max-microvolt = <3300000>;
				regulator-enable-ramp-delay = <218>;
			};

			mt6397_vmch_reg: ldo_vmch {
				regulator-name = "vmch";
				regulator-min-microvolt = <3000000>;
				regulator-max-microvolt = <3300000>;
				regulator-enable-ramp-delay = <218>;
			};

			mt6397_vemc_3v3_reg: ldo_vemc3v3 {
				regulator-name = "vemc_3v3";
				regulator-min-microvolt = <3000000>;
				regulator-max-microvolt = <3300000>;
				regulator-enable-ramp-delay = <218>;
			};

			mt6397_vgp1_reg: ldo_vgp1 {
				regulator-name = "vcamd";
				regulator-min-microvolt = <1220000>;
				regulator-max-microvolt = <3300000>;
				regulator-enable-ramp-delay = <240>;
			};

			mt6397_vgp2_reg: ldo_vgp2 {
				regulator-name = "vcamio";
				regulator-min-microvolt = <1000000>;
				regulator-max-microvolt = <3300000>;
				regulator-enable-ramp-delay = <218>;
			};

			mt6397_vgp3_reg: ldo_vgp3 {
				regulator-name = "vcamaf";
				regulator-min-microvolt = <1200000>;
				regulator-max-microvolt = <3300000>;
				regulator-enable-ramp-delay = <218>;
			};

			mt6397_vgp4_reg: ldo_vgp4 {
				/*
				 * 1.8 V, on with a consumer in the stock kernel. With it off
				 * the touch and USB-C/audio I2C buses read low (no pull-up).
				 */
				regulator-name = "vgp4";
				regulator-min-microvolt = <1800000>;
				regulator-max-microvolt = <1800000>;
				regulator-enable-ramp-delay = <218>;
				regulator-always-on;
			};

			mt6397_vgp5_reg: ldo_vgp5 {
				regulator-name = "vgp5";
				regulator-min-microvolt = <1200000>;
				regulator-max-microvolt = <3000000>;
				regulator-enable-ramp-delay = <218>;
			};

			mt6397_vgp6_reg: ldo_vgp6 {
				/* 3.3 V, on with a consumer in the stock kernel */
				regulator-name = "vgp6";
				regulator-min-microvolt = <3300000>;
				regulator-max-microvolt = <3300000>;
				regulator-enable-ramp-delay = <218>;
				regulator-always-on;
			};

			mt6397_vibr_reg: ldo_vibr {
				regulator-name = "vibr";
				regulator-min-microvolt = <1300000>;
				regulator-max-microvolt = <3300000>;
				regulator-enable-ramp-delay = <218>;
			};
		};

		rtc: rtc {
			compatible = "mediatek,mt6397-rtc";
		};
	};
};

&{/soc} {
	/*
	 * Volume keys sit on the SoC keypad matrix (stock map: key 1 = volume down,
	 * key 2 = volume up, 9 columns per row). The MT8173 keypad has the register layout
	 * the mt6779 driver expects.
	 */
	keypad@10010000 {
		compatible = "mediatek,mt6779-keypad";
		reg = <0 0x10010000 0 0x1000>;
		interrupts = <GIC_SPI 154 IRQ_TYPE_EDGE_FALLING>;
		clocks = <&infracfg CLK_INFRA_KP>;
		clock-names = "kpd";
		keypad,num-rows = <1>;
		keypad,num-columns = <3>;
		linux,keymap = <MATRIX_KEY(0, 1, KEY_VOLUMEDOWN)
				MATRIX_KEY(0, 2, KEY_VOLUMEUP)>;
		wakeup-source;
	};
};

/*
 * Display. The panel (Sharp 1536x2048, NT35523) has two DSI ports, one per half of each
 * line. The path is the one LK leaves running:
 *
 *   OVL0 -> COLOR0 -> AAL -> OD -> RDMA0 -> UFOE (left/right mode) -> SPLIT1 -> DSI0 + DSI1
 *
 * It is described as an OF graph so that mediatek-drm builds it instead of its fixed
 * MT8173 path (which ends UFOE -> DSI0). DSI1 stays disabled: DSI0 owns it as the second
 * link ("mediatek,dual-dsi-slave", bring-up property, not an upstream binding).
 *
 * The panel supplies (1.8 V on GPIO71, TPS65132 bias), its reset lines and the LP8556
 * backlight are on i2c2 and in the root node above.
 */
&mmsys {
	/* no CMDQ in this build: without this the GCE mailbox is a supplier that never probes */
	/delete-property/ mboxes;

	port {
		#address-cells = <1>;
		#size-cells = <0>;

		mmsys_main: endpoint@0 {
			reg = <0>;
			remote-endpoint = <&ovl0_in>;
		};
	};
};

&ovl0 {
	ports {
		#address-cells = <1>;
		#size-cells = <0>;

		port@0 {
			reg = <0>;
			ovl0_in: endpoint {
				remote-endpoint = <&mmsys_main>;
			};
		};

		port@1 {
			reg = <1>;
			ovl0_out: endpoint {
				remote-endpoint = <&color0_in>;
			};
		};
	};
};

&color0 {
	ports {
		#address-cells = <1>;
		#size-cells = <0>;

		port@0 {
			reg = <0>;
			color0_in: endpoint {
				remote-endpoint = <&ovl0_out>;
			};
		};

		port@1 {
			reg = <1>;
			color0_out: endpoint {
				remote-endpoint = <&aal_in>;
			};
		};
	};
};

&{/soc/aal@14015000} {
	ports {
		#address-cells = <1>;
		#size-cells = <0>;

		port@0 {
			reg = <0>;
			aal_in: endpoint {
				remote-endpoint = <&color0_out>;
			};
		};

		port@1 {
			reg = <1>;
			aal_out: endpoint {
				remote-endpoint = <&od_in>;
			};
		};
	};
};

&{/soc/od@14023000} {
	ports {
		#address-cells = <1>;
		#size-cells = <0>;

		port@0 {
			reg = <0>;
			od_in: endpoint {
				remote-endpoint = <&aal_out>;
			};
		};

		port@1 {
			reg = <1>;
			od_out: endpoint {
				remote-endpoint = <&rdma0_in>;
			};
		};
	};
};

&rdma0 {
	ports {
		#address-cells = <1>;
		#size-cells = <0>;

		port@0 {
			reg = <0>;
			rdma0_in: endpoint {
				remote-endpoint = <&od_out>;
			};
		};

		port@1 {
			reg = <1>;
			rdma0_out: endpoint {
				remote-endpoint = <&ufoe_in>;
			};
		};
	};
};

&{/soc/ufoe@1401a000} {
	mediatek,ufoe-lr-mode;

	ports {
		#address-cells = <1>;
		#size-cells = <0>;

		port@0 {
			reg = <0>;
			ufoe_in: endpoint {
				remote-endpoint = <&rdma0_out>;
			};
		};

		port@1 {
			reg = <1>;
			ufoe_out: endpoint {
				remote-endpoint = <&split1_in>;
			};
		};
	};
};

&split1 {
	ports {
		#address-cells = <1>;
		#size-cells = <0>;

		port@0 {
			reg = <0>;
			split1_in: endpoint {
				remote-endpoint = <&ufoe_out>;
			};
		};

		port@1 {
			reg = <1>;
			split1_out: endpoint {
				remote-endpoint = <&dsi0_in>;
			};
		};
	};
};

&mipi_tx0 {
	status = "okay";
};

&mipi_tx1 {
	status = "okay";
};

&dsi0 {
	status = "okay";
	#address-cells = <1>;
	#size-cells = <0>;
	mediatek,dual-dsi-slave = <&dsi1>;

	ports {
		#address-cells = <1>;
		#size-cells = <0>;

		port@0 {
			reg = <0>;
			dsi0_in: endpoint {
				remote-endpoint = <&split1_out>;
			};
		};

		port@1 {
			reg = <1>;
			dsi0_out: endpoint {
				remote-endpoint = <&panel_in>;
			};
		};
	};

	panel@0 {
		compatible = "xiaomi,cappu-nt35523";
		reg = <0>;
		vddio-supply = <&panel_1v8>;
		vsp-supply = <&panel_vsp>;
		vsn-supply = <&panel_vsn>;
		/* two reset lines in the stock driver, driven together: GPIO127 and PMIC GPIO14 */
		reset-gpios = <&pio 127 GPIO_ACTIVE_LOW>, <&pio6397 14 GPIO_ACTIVE_LOW>;
		backlight = <&backlight>;

		port {
			panel_in: endpoint {
				remote-endpoint = <&dsi0_out>;
			};
		};
	};
};
